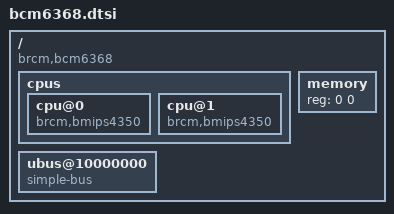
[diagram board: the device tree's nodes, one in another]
/*
 * Device Tree Include file for Broadcom BCM6368 SoC
 *
 * Copyright (C) 2012 Jonas Gorski <jonas.gorski@gmail.com>
 *
 * This file is licensed under the terms of the GNU General Public License
 * version 2.  This program is licensed "as is" without any warranty of any
 * kind, whether express or implied.
 */

/ {
	#address-cells = <1>;
	#size-cells = <1>;
	compatible = "brcm,bcm6368";

	cpus {
		cpu@0 {
			compatible = "brcm,bmips4350", "mips,mips4Kc";
		};
		cpu@1 {
			compatible = "brcm,bmips4350", "mips,mips4Kc";
		};
	};

	memory { device_type = "memory"; reg = <0 0>; };

	ubus@10000000 {
		#address-cells = <1>;
		#size-cells = <1>;
		ranges = <0 0x10000000 0x20000>;
		compatible = "simple-bus";
	};
};
